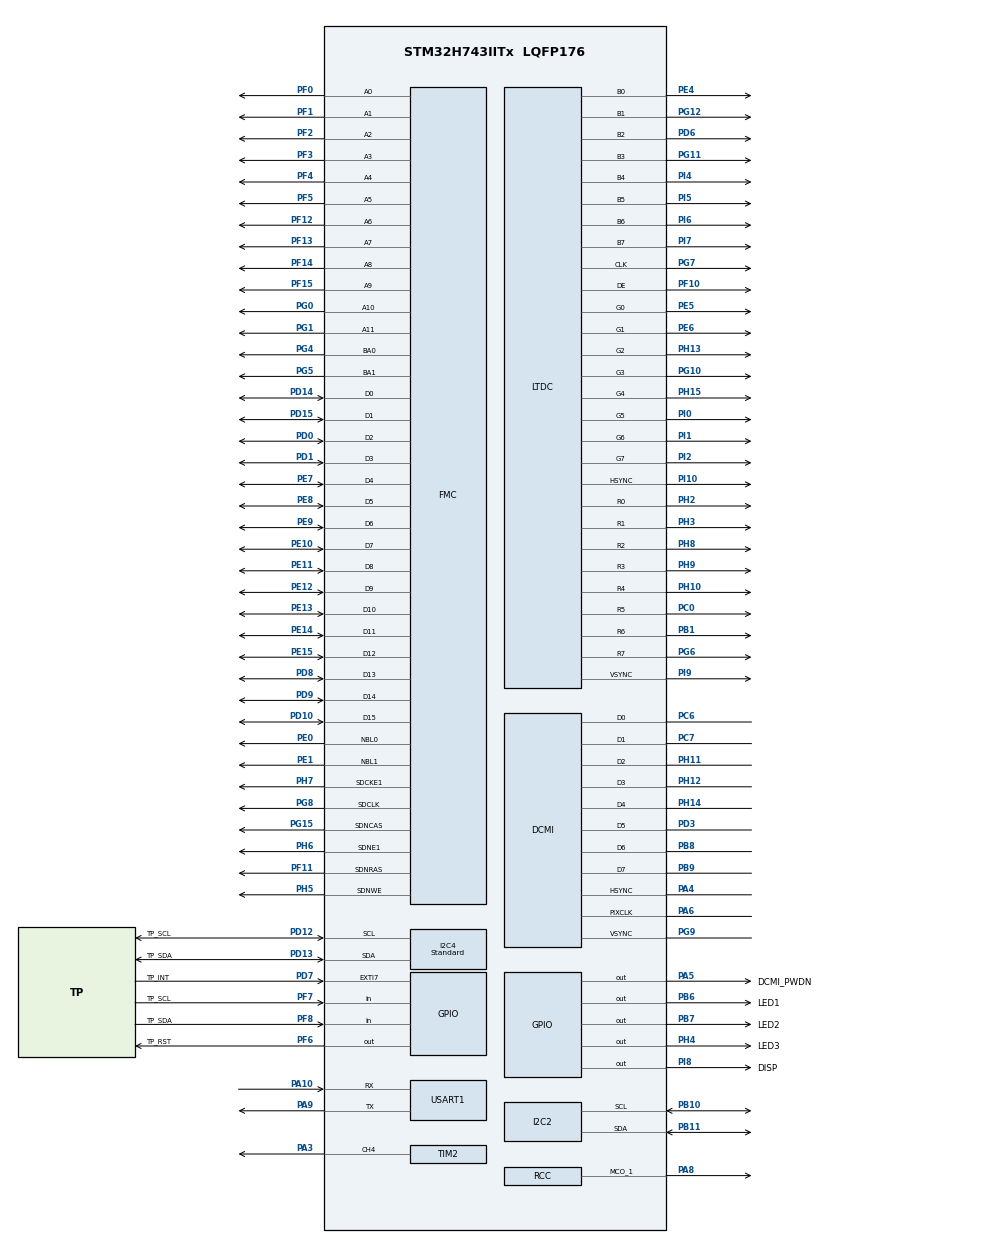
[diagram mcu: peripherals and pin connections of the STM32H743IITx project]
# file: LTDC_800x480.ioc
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CORTEX_M7.BaseAddress-Cortex_Memory_Protection_Unit_Region0_Settings=0xD0000000
CORTEX_M7.BaseAddress-Cortex_Memory_Protection_Unit_Region1_Settings=0x38000000
CORTEX_M7.CPU_DCache=Disabled
CORTEX_M7.CPU_ICache=Enabled
CORTEX_M7.Enable-Cortex_Memory_Protection_Unit_Region0_Settings=MPU_REGION_ENABLE
CORTEX_M7.Enable-Cortex_Memory_Protection_Unit_Region1_Settings=MPU_REGION_ENABLE
CORTEX_M7.MPU_Control=__NULL
CORTEX_M7.Size-Cortex_Memory_Protection_Unit_Region0_Settings=MPU_REGION_SIZE_8MB
CORTEX_M7.Size-Cortex_Memory_Protection_Unit_Region1_Settings=MPU_REGION_SIZE_512KB
CORTEX_M7.TypeExtField-Cortex_Memory_Protection_Unit_Region0_Settings=MPU_TEX_LEVEL1
CORTEX_M7.TypeExtField-Cortex_Memory_Protection_Unit_Region1_Settings=MPU_TEX_LEVEL1
DCMI.PCKPolarity=DCMI_PCKPOLARITY_RISING
DCMI.VSPolarity=DCMI_VSPOLARITY_HIGH
DMA2D.ColorMode=DMA2D_OUTPUT_RGB565
Dma.DCMI.0.Direction=DMA_PERIPH_TO_MEMORY
Dma.DCMI.0.EventEnable=DISABLE
Dma.DCMI.0.FIFOMode=DMA_FIFOMODE_ENABLE
Dma.DCMI.0.FIFOThreshold=DMA_FIFO_THRESHOLD_FULL
Dma.DCMI.0.Instance=DMA2_Stream0
Dma.DCMI.0.MemBurst=DMA_MBURST_SINGLE
Dma.DCMI.0.MemDataAlignment=DMA_MDATAALIGN_WORD
Dma.DCMI.0.MemInc=DMA_MINC_ENABLE
Dma.DCMI.0.Mode=DMA_NORMAL
Dma.DCMI.0.PeriphBurst=DMA_PBURST_SINGLE
Dma.DCMI.0.PeriphDataAlignment=DMA_PDATAALIGN_WORD
Dma.DCMI.0.PeriphInc=DMA_PINC_DISABLE
Dma.DCMI.0.Polarity=HAL_DMAMUX_REQ_GEN_RISING
Dma.DCMI.0.Priority=DMA_PRIORITY_MEDIUM
Dma.DCMI.0.RequestNumber=1
Dma.DCMI.0.SignalID=NONE
Dma.DCMI.0.SyncEnable=DISABLE
Dma.DCMI.0.SyncPolarity=HAL_DMAMUX_SYNC_NO_EVENT
Dma.DCMI.0.SyncRequestNumber=1
Dma.DCMI.0.SyncSignalID=NONE
Dma.Request0=DCMI
Dma.Request1=USART1_TX
Dma.USART1_TX.1.Direction=DMA_MEMORY_TO_PERIPH
Dma.USART1_TX.1.EventEnable=DISABLE
Dma.USART1_TX.1.FIFOMode=DMA_FIFOMODE_DISABLE
Dma.USART1_TX.1.Instance=DMA1_Stream1
Dma.USART1_TX.1.MemDataAlignment=DMA_MDATAALIGN_BYTE
Dma.USART1_TX.1.MemInc=DMA_MINC_ENABLE
Dma.USART1_TX.1.Mode=DMA_NORMAL
Dma.USART1_TX.1.PeriphDataAlignment=DMA_PDATAALIGN_BYTE
Dma.USART1_TX.1.PeriphInc=DMA_PINC_DISABLE
Dma.USART1_TX.1.Polarity=HAL_DMAMUX_REQ_GEN_RISING
Dma.USART1_TX.1.Priority=DMA_PRIORITY_LOW
Dma.USART1_TX.1.RequestNumber=1
Dma.USART1_TX.1.SignalID=NONE
Dma.USART1_TX.1.SyncEnable=DISABLE
Dma.USART1_TX.1.SyncPolarity=HAL_DMAMUX_SYNC_NO_EVENT
Dma.USART1_TX.1.SyncRequestNumber=1
Dma.USART1_TX.1.SyncSignalID=NONE
FMC.CASLatency1=FMC_SDRAM_CAS_LATENCY_3
FMC.ExitSelfRefreshDelay1=7
FMC.LoadToActiveDelay1=2
FMC.RCDDelay1=2
FMC.RPDelay1=2
FMC.ReadPipeDelay1=FMC_SDRAM_RPIPE_DELAY_1
FMC.RowCycleDelay1=6
FMC.SDClockPeriod1=FMC_SDRAM_CLOCK_PERIOD_2
FMC.SelfRefreshTime1=4
FMC.WriteRecoveryTime1=2
I2C2.Timing=0x20303E5D
I2C4.CustomTiming=Disabled
I2C4.DualAddressMode=I2C_DUALADDRESS_DISABLE
I2C4.GeneralCallMode=I2C_GENERALCALL_DISABLE
I2C4.I2C_Speed_Mode=I2C_Standard
I2C4.NoStretchMode=I2C_NOSTRETCH_ENABLE
I2C4.Timing=0x20303E5D
LTDC.ActiveW=800
LTDC.Alpha_L0=0xff
LTDC.FBStartAdress_L0=0xD0000000
LTDC.FBStartAdress_L1=0xD0200000
LTDC.HBP=46
LTDC.HFP=6
LTDC.HSync=30
LTDC.ImageHeight_L0=480
LTDC.ImageHeight_L1=480
LTDC.ImageWidth_L0=800
LTDC.Layers=0
LTDC.PixelFormat_L0=LTDC_PIXEL_FORMAT_RGB565
LTDC.VBP=23
LTDC.VFP=22
LTDC.VSync=10
LTDC.WindowX1_L0=800
LTDC.WindowX1_L1=800
LTDC.WindowY1_L0=480
LTDC.WindowY1_L1=480
Mcu.Family=STM32H7
Mcu.Name=STM32H743IITx
Mcu.Package=LQFP176
NVIC.DCMI_IRQn=true\:0\:0\:false\:false\:true\:true\:true\:true
NVIC.DMA1_Stream1_IRQn=true\:0\:0\:false\:false\:true\:false\:true\:true
NVIC.DMA2D_IRQn=true\:0\:0\:false\:false\:true\:true\:true\:true
NVIC.DMA2_Stream0_IRQn=true\:0\:0\:false\:false\:true\:false\:true\:true
NVIC.EXTI9_5_IRQn=true\:0\:0\:false\:false\:true\:true\:true\:true
NVIC.LTDC_IRQn=true\:0\:0\:false\:false\:true\:true\:true\:true
NVIC.PriorityGroup=NVIC_PRIORITYGROUP_4
NVIC.USART1_IRQn=true\:0\:0\:false\:false\:true\:true\:true\:true
PA10.Mode=Asynchronous
PA10.Signal=USART1_RX
PA3.Signal=S_TIM2_CH4
PA4.GPIO_Speed=GPIO_SPEED_FREQ_VERY_HIGH
PA4.Mode=Slave_8_bits_External_Synchro
PA4.Signal=DCMI_HSYNC
PA5.GPIO_Label=DCMI_PWDN
PA5.PinState=GPIO_PIN_RESET
PA5.Signal=GPIO_Output
PA6.GPIO_Speed=GPIO_SPEED_FREQ_VERY_HIGH
PA6.Mode=Slave_8_bits_External_Synchro
PA6.Signal=DCMI_PIXCLK
PA8.Mode=Clock-out-1
PA8.Signal=RCC_MCO_1
PA9.Mode=Asynchronous
PA9.Signal=USART1_TX
PB1.GPIO_Speed=GPIO_SPEED_FREQ_LOW
PB1.Mode=RGB888
PB1.Signal=LTDC_R6
PB10.GPIO_Pu=GPIO_PULLUP
PB10.GPIO_Speed=GPIO_SPEED_FREQ_HIGH
PB10.Mode=I2C
PB10.Signal=I2C2_SCL
PB11.GPIO_Pu=GPIO_PULLUP
PB11.GPIO_Speed=GPIO_SPEED_FREQ_HIGH
PB11.Mode=I2C
PB11.Signal=I2C2_SDA
PB6.GPIO_Label=LED1
PB6.Signal=GPIO_Output
PB7.GPIO_Label=LED2
PB7.Signal=GPIO_Output
PB8.GPIO_FM8=__NULL
PB8.GPIO_Speed=GPIO_SPEED_FREQ_VERY_HIGH
PB8.Mode=Slave_8_bits_External_Synchro
PB8.Signal=DCMI_D6
PB9.GPIO_FM9=__NULL
PB9.GPIO_Speed=GPIO_SPEED_FREQ_VERY_HIGH
PB9.Mode=Slave_8_bits_External_Synchro
PB9.Signal=DCMI_D7
PC0.Mode=RGB888
PC0.Signal=LTDC_R5
PC6.GPIO_Speed=GPIO_SPEED_FREQ_VERY_HIGH
PC6.Mode=Slave_8_bits_External_Synchro
PC6.Signal=DCMI_D0
PC7.GPIO_Speed=GPIO_SPEED_FREQ_VERY_HIGH
PC7.Mode=Slave_8_bits_External_Synchro
PC7.Signal=DCMI_D1
PD0.Signal=FMC_D2_DA2
PD1.Signal=FMC_D3_DA3
PD10.Signal=FMC_D15_DA15
PD12.GPIO_Label=TP_SCL
PD12.GPIO_Pu=GPIO_PULLUP
PD12.GPIO_PuPd=GPIO_PULLUP
PD12.GPIO_Speed=GPIO_SPEED_FREQ_HIGH
PD12.Mode=I2C
PD12.Signal=I2C4_SCL
PD13.GPIO_Label=TP_SDA
PD13.GPIO_Pu=GPIO_PULLUP
PD13.GPIO_PuPd=GPIO_PULLUP
PD13.GPIO_Speed=GPIO_SPEED_FREQ_HIGH
PD13.Mode=I2C
PD13.Signal=I2C4_SDA
PD14.Signal=FMC_D0_DA0
PD15.Signal=FMC_D1_DA1
PD3.GPIO_Speed=GPIO_SPEED_FREQ_VERY_HIGH
PD3.Mode=Slave_8_bits_External_Synchro
PD3.Signal=DCMI_D5
PD6.Mode=RGB888
PD6.Signal=LTDC_B2
PD7.GPIO_Label=TP_INT
PD7.GPIO_PuPd=GPIO_PULLUP
PD7.Signal=GPXTI7
PD8.Signal=FMC_D13_DA13
PD9.Signal=FMC_D14_DA14
PE0.Signal=FMC_NBL0
PE1.Signal=FMC_NBL1
PE10.Signal=FMC_D7_DA7
PE11.Signal=FMC_D8_DA8
PE12.Signal=FMC_D9_DA9
PE13.Signal=FMC_D10_DA10
PE14.Signal=FMC_D11_DA11
PE15.Signal=FMC_D12_DA12
PE4.Mode=RGB888
PE4.Signal=LTDC_B0
PE5.Mode=RGB888
PE5.Signal=LTDC_G0
PE6.Mode=RGB888
PE6.Signal=LTDC_G1
PE7.Signal=FMC_D4_DA4
PE8.Signal=FMC_D5_DA5
PE9.Signal=FMC_D6_DA6
PF0.Signal=FMC_A0
PF1.Signal=FMC_A1
PF10.Mode=RGB888
PF10.Signal=LTDC_DE
PF11.Signal=FMC_SDNRAS
PF12.Signal=FMC_A6
PF13.Signal=FMC_A7
PF14.Signal=FMC_A8
PF15.Signal=FMC_A9
PF2.Signal=FMC_A2
PF3.Signal=FMC_A3
PF4.Signal=FMC_A4
PF5.Signal=FMC_A5
PF6.GPIO_Label=TP_RST
PF6.Signal=GPIO_Output
PF7.GPIO_Label=TP_SCL
PF7.Signal=GPIO_Input
PF8.GPIO_Label=TP_SDA
PF8.GPIO_PuPd=GPIO_PULLUP
PF8.Signal=GPIO_Input
PG0.Signal=FMC_A10
PG1.Signal=FMC_A11
PG10.Mode=RGB888
PG10.Signal=LTDC_G3
PG11.Mode=RGB888
PG11.Signal=LTDC_B3
PG12.Mode=RGB888
PG12.Signal=LTDC_B1
PG15.Signal=FMC_SDNCAS
PG4.Signal=FMC_A14_BA0
PG5.Signal=FMC_A15_BA1
PG6.Mode=RGB888
PG6.Signal=LTDC_R7
PG7.GPIO_Speed=GPIO_SPEED_FREQ_VERY_HIGH
PG7.Mode=RGB888
PG7.Signal=LTDC_CLK
PG8.Signal=FMC_SDCLK
PG9.GPIO_Speed=GPIO_SPEED_FREQ_VERY_HIGH
PG9.Mode=Slave_8_bits_External_Synchro
PG9.Signal=DCMI_VSYNC
PH0-OSC_IN\ (PH0).Mode=HSE-External-Oscillator
PH0-OSC_IN\ (PH0).Signal=RCC_OSC_IN
PH1-OSC_OUT\ (PH1).Mode=HSE-External-Oscillator
PH1-OSC_OUT\ (PH1).Signal=RCC_OSC_OUT
PH10.Mode=RGB888
PH10.Signal=LTDC_R4
PH11.GPIO_Speed=GPIO_SPEED_FREQ_VERY_HIGH
PH11.Mode=Slave_8_bits_External_Synchro
PH11.Signal=DCMI_D2
PH12.GPIO_Speed=GPIO_SPEED_FREQ_VERY_HIGH
PH12.Mode=Slave_8_bits_External_Synchro
PH12.Signal=DCMI_D3
PH13.Mode=RGB888
PH13.Signal=LTDC_G2
PH14.GPIO_Speed=GPIO_SPEED_FREQ_VERY_HIGH
PH14.Mode=Slave_8_bits_External_Synchro
PH14.Signal=DCMI_D4
PH15.Mode=RGB888
PH15.Signal=LTDC_G4
PH2.Mode=RGB888
PH2.Signal=LTDC_R0
PH3.Mode=RGB888
PH3.Signal=LTDC_R1
PH4.GPIO_Label=LED3
PH4.Signal=GPIO_Output
PH5.Signal=FMC_SDNWE
PH6.Mode=SdramChipSelect2_1
PH6.Signal=FMC_SDNE1
PH7.Mode=SdramChipSelect2_1
PH7.Signal=FMC_SDCKE1
PH8.Mode=RGB888
PH8.Signal=LTDC_R2
PH9.Mode=RGB888
PH9.Signal=LTDC_R3
PI0.Mode=RGB888
PI0.Signal=LTDC_G5
PI1.Mode=RGB888
PI1.Signal=LTDC_G6
PI10.GPIO_Speed=GPIO_SPEED_FREQ_VERY_HIGH
PI10.Mode=RGB888
PI10.Signal=LTDC_HSYNC
PI2.Mode=RGB888
PI2.Signal=LTDC_G7
PI4.Mode=RGB888
PI4.Signal=LTDC_B4
PI5.Mode=RGB888
PI5.Signal=LTDC_B5
PI6.Mode=RGB888
PI6.Signal=LTDC_B6
PI7.Mode=RGB888
PI7.Signal=LTDC_B7
PI8.GPIO_Label=DISP
PI8.PinState=GPIO_PIN_SET
PI8.Signal=GPIO_Output
PI9.GPIO_Speed=GPIO_SPEED_FREQ_VERY_HIGH
PI9.Mode=RGB888
PI9.Signal=LTDC_VSYNC
ProjectManager.HeapSize=0x200
ProjectManager.StackSize=0x400
ProjectManager.TargetToolchain=STM32CubeIDE
RCC.ADCFreq_Value=100000000
RCC.APB1Freq_Value=48000000
RCC.APB2Freq_Value=48000000
RCC.APB3Freq_Value=96000000
RCC.APB4Freq_Value=48000000
RCC.CortexFreq_Value=384000000
RCC.D1PPRE=RCC_APB3_DIV2
RCC.D2PPRE1=RCC_APB1_DIV4
RCC.D2PPRE2=RCC_APB2_DIV4
RCC.D3PPRE=RCC_APB4_DIV4
RCC.DIVM1=4
RCC.DIVM2=4
RCC.DIVM3=4
RCC.DIVN1=384
RCC.DIVN2=100
RCC.DIVN3=96
RCC.DIVQ1=16
RCC.DIVQ3=4
RCC.DIVR3=9
RCC.HCLKFreq_Value=192000000
RCC.HPRE=RCC_HCLK_DIV2
RCC.HSE_VALUE=8000000
RCC.PLLSourceVirtual=RCC_PLLSOURCE_HSE
RCC.PWR_Regulator_Voltage_Scale=PWR_REGULATOR_VOLTAGE_SCALE1
RCC.RCC_MCO1Source=RCC_MCO1SOURCE_PLL1QCLK
RCC.RCC_MCODiv1=RCC_MCODIV_2
RCC.SYSCLKFreq_VALUE=384000000
RCC.SYSCLKSource=RCC_SYSCLKSOURCE_PLLCLK
RCC.USBFreq_Value=48000000
SH.FMC_A0.0=FMC_A0,12b-sda1
SH.FMC_A1.0=FMC_A1,12b-sda1
SH.FMC_A10.0=FMC_A10,12b-sda1
SH.FMC_A11.0=FMC_A11,12b-sda1
SH.FMC_A14_BA0.0=FMC_BA0,FourSdramBanks1
SH.FMC_A15_BA1.0=FMC_BA1,FourSdramBanks1
SH.FMC_A2.0=FMC_A2,12b-sda1
SH.FMC_A3.0=FMC_A3,12b-sda1
SH.FMC_A4.0=FMC_A4,12b-sda1
SH.FMC_A5.0=FMC_A5,12b-sda1
SH.FMC_A6.0=FMC_A6,12b-sda1
SH.FMC_A7.0=FMC_A7,12b-sda1
SH.FMC_A8.0=FMC_A8,12b-sda1
SH.FMC_A9.0=FMC_A9,12b-sda1
SH.FMC_D0_DA0.0=FMC_D0,sd-16b-d1
SH.FMC_D10_DA10.0=FMC_D10,sd-16b-d1
SH.FMC_D11_DA11.0=FMC_D11,sd-16b-d1
SH.FMC_D12_DA12.0=FMC_D12,sd-16b-d1
SH.FMC_D13_DA13.0=FMC_D13,sd-16b-d1
SH.FMC_D14_DA14.0=FMC_D14,sd-16b-d1
SH.FMC_D15_DA15.0=FMC_D15,sd-16b-d1
SH.FMC_D1_DA1.0=FMC_D1,sd-16b-d1
SH.FMC_D2_DA2.0=FMC_D2,sd-16b-d1
SH.FMC_D3_DA3.0=FMC_D3,sd-16b-d1
SH.FMC_D4_DA4.0=FMC_D4,sd-16b-d1
SH.FMC_D5_DA5.0=FMC_D5,sd-16b-d1
SH.FMC_D6_DA6.0=FMC_D6,sd-16b-d1
SH.FMC_D7_DA7.0=FMC_D7,sd-16b-d1
SH.FMC_D8_DA8.0=FMC_D8,sd-16b-d1
SH.FMC_D9_DA9.0=FMC_D9,sd-16b-d1
SH.FMC_NBL0.0=FMC_NBL0,Sd2ByteEnable1
SH.FMC_NBL1.0=FMC_NBL1,Sd2ByteEnable1
SH.FMC_SDCLK.0=FMC_SDCLK,12b-sda1
SH.FMC_SDNCAS.0=FMC_SDNCAS,12b-sda1
SH.FMC_SDNRAS.0=FMC_SDNRAS,12b-sda1
SH.FMC_SDNWE.0=FMC_SDNWE,12b-sda1
SH.S_TIM2_CH4.0=TIM2_CH4,PWM Generation4 CH4
TIM2.AutoReloadPreload=TIM_AUTORELOAD_PRELOAD_ENABLE
TIM2.Channel-PWM\ Generation4\ CH4=TIM_CHANNEL_4
TIM2.Period=1000-1
TIM2.Prescaler=100-1
TIM2.Pulse-PWM\ Generation4\ CH4=500
USART1.VirtualMode-Asynchronous=VM_ASYNC
VP_CRC_VS_CRC.Mode=CRC_Activate
VP_DMA2D_VS_DMA2D.Mode=DMA2D_Activate
VP_MEMORYMAP_VS_MEMORYMAP.Mode=CurAppReg
board=custom

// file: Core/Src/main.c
/* USER CODE BEGIN Header */
/**
 ******************************************************************************
 * @file           : main.c
 * @brief          : Main program body
 ******************************************************************************
 * @attention
 *
 * Copyright (c) 2025 STMicroelectronics.
 * All rights reserved.
 *
 * This software is licensed under terms that can be found in the LICENSE file
 * in the root directory of this software component.
 * If no LICENSE file comes with this software, it is provided AS-IS.
 *
 ******************************************************************************
 */
/* USER CODE END Header */
#include "main.h"
#include "crc.h"
#include "dcmi.h"
#include "dma.h"
#include "dma2d.h"
#include "i2c.h"
#include "ltdc.h"
#include "memorymap.h"
#include "tim.h"
#include "usart.h"
#include "gpio.h"
#include "fmc.h"

/* USER CODE BEGIN Includes */
#include "BSP_SDRAM.h"
#include "BSP_RGB_LCD.h"
#include "GUI_Paint.h"
#include "image.h"
#include "debug_console.h"
#include "ov7670/ov7670.h"

/* USER CODE END Includes */

/* USER CODE BEGIN PV */
static char IsFrameReady = 0;
extern uint8_t img_buffer[];

void FrameTask()
{
	if (IsFrameReady)
	{
		BSP_LCD_FillRGBRect((DISPLAY_WIDTH-OV7670_WIDTH)/2, (DISPLAY_HEIGHT-OV7670_HEIGHT)/2,
				img_buffer, OV7670_WIDTH, OV7670_HEIGHT);
		IsFrameReady = 0;
	}
}

/* USER CODE END PV */

void SystemClock_Config(void);

int main(void)
{

  /* Enable the CPU Cache */

  /* Enable I-Cache---------------------------------------------------------*/
  SCB_EnableICache();

  /* MCU Configuration--------------------------------------------------------*/

  /* Reset of all peripherals, Initializes the Flash interface and the Systick. */
  HAL_Init();

  /* Configure the system clock */
  SystemClock_Config();

  /* Initialize all configured peripherals */
  MX_GPIO_Init();
  MX_DMA_Init();
  MX_FMC_Init();
  MX_USART1_UART_Init();
  MX_LTDC_Init();
  MX_DMA2D_Init();
  MX_TIM2_Init();
  MX_CRC_Init();
  MX_I2C4_Init();
  MX_DCMI_Init();
  MX_I2C2_Init();
  /* USER CODE BEGIN 2 */
	printf("******** LTDC Example ********\r\n");
	HAL_GPIO_WritePin(DISP_GPIO_Port, DISP_Pin, GPIO_PIN_SET);
	HAL_TIM_PWM_Start(&htim2, TIM_CHANNEL_4);
	TIM2->CCR4 = 500;
	BSP_LCD_Init();
	HAL_Delay(50);
	BSP_LCD_Clear(0);

	//Pixel  800*480  RGB565
	Paint_NewImage(800, 480, 0, 0xffff);
	Paint_Clear(0xffff);
	Paint_DrawString_EN(10, 230, "1234567890", &Font24, 0x000f, 0xfff0);
	Paint_DrawString_EN(10, 260, "ABCDEFGHIJ", &Font24, BLUE, CYAN);
	Paint_DrawString_CN(10, 290, "΢ѩ����", &Font24CN, BLUE, CYAN);

	Paint_DrawRectangle(200, 230, 300, 330, RED, DRAW_FILL_EMPTY,
			DOT_PIXEL_2X2);
	Paint_DrawLine(200, 230, 300, 330, MAGENTA, LINE_STYLE_SOLID,
			DOT_PIXEL_2X2);
	Paint_DrawLine(300, 230, 200, 330, MAGENTA, LINE_STYLE_SOLID,
			DOT_PIXEL_2X2);
	Paint_DrawCircle(250, 280, 45, GREEN, DRAW_FILL_EMPTY, DOT_PIXEL_2X2);
	Paint_DrawImage(gImage_800X221, 0, 0, 800, 221);
	HAL_Delay(1000);

  /* USER CODE END 2 */

  /* Infinite loop */
  /* USER CODE BEGIN WHILE */
	DebugInit();
	OV7670_Init(&hdcmi, &hi2c_dcmi, 0, 0);
	OV7670_Start();

	while (1)
	{
    /* USER CODE END WHILE */

    /* USER CODE BEGIN 3 */
#if 1
		FrameTask();
		DebugTask();
		HAL_GPIO_WritePin(LED1_GPIO_Port, LED1_Pin, GPIO_PIN_SET);
		HAL_Delay(100);
		FrameTask();
		DebugTask();
		HAL_GPIO_WritePin(LED1_GPIO_Port, LED1_Pin, GPIO_PIN_RESET);
		HAL_Delay(100);
#else
		HAL_GPIO_WritePin(LED1_GPIO_Port, LED1_Pin, GPIO_PIN_SET);
		HAL_Delay(1000);
		BSP_LCD_Clear(0xf000);
		HAL_GPIO_WritePin(LED2_GPIO_Port, LED2_Pin, GPIO_PIN_SET);
		HAL_Delay(1000);
		BSP_LCD_Clear(0x0f00);
		HAL_GPIO_WritePin(LED3_GPIO_Port, LED3_Pin, GPIO_PIN_SET);
		HAL_Delay(1000);
		BSP_LCD_Clear(0x00f0);
		HAL_GPIO_WritePin(LED1_GPIO_Port, LED1_Pin, GPIO_PIN_RESET);
		HAL_Delay(1000);
		BSP_LCD_Clear(0x000f);
		HAL_GPIO_WritePin(LED2_GPIO_Port, LED2_Pin, GPIO_PIN_RESET);
		HAL_Delay(1000);
		BSP_LCD_Clear(0xf00f);
		HAL_GPIO_WritePin(LED3_GPIO_Port, LED3_Pin, GPIO_PIN_RESET);
		HAL_Delay(1000);
#endif
	}
  /* USER CODE END 3 */
}

void SystemClock_Config(void)
{
  RCC_OscInitTypeDef RCC_OscInitStruct = {0};
  RCC_ClkInitTypeDef RCC_ClkInitStruct = {0};

  /** Supply configuration update enable
  */
  HAL_PWREx_ConfigSupply(PWR_LDO_SUPPLY);

  /** Configure the main internal regulator output voltage
  */
  __HAL_PWR_VOLTAGESCALING_CONFIG(PWR_REGULATOR_VOLTAGE_SCALE1);

  while(!__HAL_PWR_GET_FLAG(PWR_FLAG_VOSRDY)) {}

  /** Initializes the RCC Oscillators according to the specified parameters
  * in the RCC_OscInitTypeDef structure.
  */
  RCC_OscInitStruct.OscillatorType = RCC_OSCILLATORTYPE_HSE;
  RCC_OscInitStruct.HSEState = RCC_HSE_ON;
  RCC_OscInitStruct.PLL.PLLState = RCC_PLL_ON;
  RCC_OscInitStruct.PLL.PLLSource = RCC_PLLSOURCE_HSE;
  RCC_OscInitStruct.PLL.PLLM = 4;
  RCC_OscInitStruct.PLL.PLLN = 384;
  RCC_OscInitStruct.PLL.PLLP = 2;
  RCC_OscInitStruct.PLL.PLLQ = 16;
  RCC_OscInitStruct.PLL.PLLR = 2;
  RCC_OscInitStruct.PLL.PLLRGE = RCC_PLL1VCIRANGE_1;
  RCC_OscInitStruct.PLL.PLLVCOSEL = RCC_PLL1VCOWIDE;
  RCC_OscInitStruct.PLL.PLLFRACN = 0;
  if (HAL_RCC_OscConfig(&RCC_OscInitStruct) != HAL_OK)
  {
    Error_Handler();
  }

  /** Initializes the CPU, AHB and APB buses clocks
  */
  RCC_ClkInitStruct.ClockType = RCC_CLOCKTYPE_HCLK|RCC_CLOCKTYPE_SYSCLK
                              |RCC_CLOCKTYPE_PCLK1|RCC_CLOCKTYPE_PCLK2
                              |RCC_CLOCKTYPE_D3PCLK1|RCC_CLOCKTYPE_D1PCLK1;
  RCC_ClkInitStruct.SYSCLKSource = RCC_SYSCLKSOURCE_PLLCLK;
  RCC_ClkInitStruct.SYSCLKDivider = RCC_SYSCLK_DIV1;
  RCC_ClkInitStruct.AHBCLKDivider = RCC_HCLK_DIV2;
  RCC_ClkInitStruct.APB3CLKDivider = RCC_APB3_DIV2;
  RCC_ClkInitStruct.APB1CLKDivider = RCC_APB1_DIV4;
  RCC_ClkInitStruct.APB2CLKDivider = RCC_APB2_DIV4;
  RCC_ClkInitStruct.APB4CLKDivider = RCC_APB4_DIV4;

  if (HAL_RCC_ClockConfig(&RCC_ClkInitStruct, FLASH_LATENCY_2) != HAL_OK)
  {
    Error_Handler();
  }
  __HAL_RCC_PLLCLKOUT_ENABLE(RCC_PLL1_DIVQ);
  HAL_RCC_MCOConfig(RCC_MCO1, RCC_MCO1SOURCE_PLL1QCLK, RCC_MCODIV_2);
}

/* USER CODE BEGIN 4 */

HAL_StatusTypeDef ov7670_write(uint8_t regAddr, uint8_t data);

void VSync_CB(const uint8_t *buffer, uint32_t buf_size)
{
	UNUSED(buffer); UNUSED(buf_size);
	IsFrameReady = 1;
}

void DebugMain(uint32_t val)
{
	switch (val) {
	case 0:
	{
#if	1
		DebugPrint("\r\n OV7670_Init(&hdcmi, &hi2c_dcmi, 0, 0);");
		OV7670_Init(&hdcmi, &hi2c_dcmi, 0, 0);
		OV7670_Start();
#else
		DebugPrint("\r\n ov7670_init(&hdcmi, &hdma_dcmi, &hi2c_dcmi);");
		ov7670_init(&hdcmi, &hdma_dcmi, &hi2c_dcmi);
		ov7670_config(OV7670_MODE_QVGA_RGB565);
		uint32_t p_lcdData = 0xD0000000;
		ov7670_startCap(OV7670_CAP_CONTINUOUS, p_lcdData);
#endif
	}
		break;
	case 1:
	{
#if 1
		uint8_t temp1, temp2;
		if (ov7670_read(OV7670_REG_PID, &temp1)==HAL_OK)
		{
			ov7670_read(OV7670_REG_VER, &temp2);
			DebugPrint("\r\n ReadID %02X %02X", temp1, temp2);
		}
		else
		{
			DebugPrint("\r\n ReadID Error!");
		}
#else
		OV7670_IDTypeDef OV7670ID = {0};
		if (!DCMI_OV7670_ReadID(&OV7670ID))
		{
			DebugPrint("\r\n ReadID %02X %02X %02X %02X);",
					OV7670ID.Manufacturer_ID1, OV7670ID.Manufacturer_ID2,
					OV7670ID.PID, OV7670ID.Version);
		}
		else
		{
			DebugPrint("\r\n ReadID Error!");
		}
#endif
	}
		break;
	case 2:
	{
#ifdef	CAMERA_SCL_Pin
		DebugPrint("\r\n HAL_GPIO_WritePin(CAMERA_SCL_GPIO_Port, CAMERA_SCL_Pin, GPIO_PIN_RESET);");
		HAL_GPIO_WritePin(CAMERA_SCL_GPIO_Port, CAMERA_SCL_Pin, GPIO_PIN_RESET);
#else
		//HAL_StatusTypeDef ret = ov7670_write(0x12, 0x80);  // RESET
		//DebugPrint("\r\n ov7670_write(0x12, 0x80) = %08lX", ret);
		if (OV7670_isDriverBusy()) {
			DebugPrint("\r\n OV7670_isDriver is Busy");
		} else {
			DebugPrint("\r\n OV7670_isDriver is NOY Busy");
		}
#endif
	}
		break;
	case 3:
	{
#ifdef	CAMERA_SCL_Pin
		DebugPrint("\r\n HAL_GPIO_WritePin(CAMERA_SDA_GPIO_Port, CAMERA_SDA_Pin, GPIO_PIN_RESET);");
		HAL_GPIO_WritePin(CAMERA_SDA_GPIO_Port, CAMERA_SDA_Pin, GPIO_PIN_RESET);
#else
		//uint8_t ret = DCMI_SingleRandomWrite(OV7670_COM7, SCCB_REG_RESET);
		DebugPrint("\r\n Clearing camera buffer");
		uint16_t *buffer = (uint16_t *)img_buffer;
	#if 1
		for (int i = 0; i<(OV7670_WIDTH*OV7670_HEIGHT); i++)
		{
			*buffer = 0;
			buffer++;
		}
	#else
		for (int i = 0; i<480; i++)
		{
			uint16_t *line_buffer = buffer;
			buffer += 1600;
			for (int j = 0; j<640; j++) {
				line_buffer[i] = 0xFF;
				line_buffer++;
			}
		}
	#endif
#endif
	}
		break;
	case 4:
	{
#if	(defined(CAMERA_SCL_Pin)&&defined(CAMERA_SDA_Pin))
		DebugPrint("\r\n HAL_GPIO_WritePin(CAMERA_GPIO_Port, CAMERA_Pin, GPIO_PIN_SET);");
		HAL_GPIO_WritePin(CAMERA_SCL_GPIO_Port, CAMERA_SCL_Pin, GPIO_PIN_SET);
		HAL_GPIO_WritePin(CAMERA_SDA_GPIO_Port, CAMERA_SDA_Pin, GPIO_PIN_SET);
//#else
//		DebugPrint("\r\n BSP_LCD_FillRGBRect();");
//		BSP_LCD_FillRGBRect((DISPLAY_WIDTH-OV7670_WIDTH)/2, (DISPLAY_HEIGHT-OV7670_HEIGHT)/2,
//				img_buffer, OV7670_WIDTH, OV7670_HEIGHT);
#else
		DebugPrint("\r\n BSP_LCD_FillRGBRect();");
		BSP_LCD_FillRGBRect((DISPLAY_WIDTH-OV7670_WIDTH)/2, (DISPLAY_HEIGHT-OV7670_HEIGHT)/2,
				img_buffer, OV7670_WIDTH, OV7670_HEIGHT);
#endif
	}
		break;
	case 5:
	{
#if 1
		DebugPrint("\r\n Paint_DrawImage(img_buffer, 0, 0, OV7670_WIDTH, OV7670_HEIGHT);");
		Paint_DrawImage(img_buffer, (DISPLAY_WIDTH-OV7670_WIDTH)/2,
				(DISPLAY_HEIGHT-OV7670_HEIGHT)/2,
				OV7670_WIDTH, OV7670_HEIGHT);
#endif
	}
		break;
	case 6:
	{
		BSP_LCD_Clear(MAGENTA);
	}
		break;
	case 7:
	{
		OV7670_RegisterCallback(OV7670_DRAWFRAME_CBK, (OV7670_FncPtr_t)VSync_CB);
	}
		break;
	}

}

/* USER CODE END 4 */

void Error_Handler(void)
{
	__disable_irq();
	while (1)
	{
	}
}
